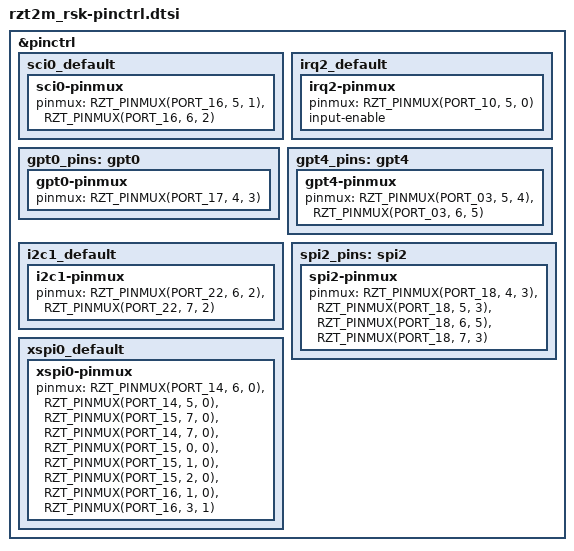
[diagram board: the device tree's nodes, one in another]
/*
 * Copyright (c) 2025 Renesas Electronics Corporation
 * SPDX-License-Identifier: Apache-2.0
 */

#include <zephyr/dt-bindings/gpio/gpio.h>
#include <zephyr/dt-bindings/pinctrl/renesas/pinctrl-rzt-common.h>

&pinctrl {
	/omit-if-no-ref/ sci0_default: sci0_default {
		sci0-pinmux {
			pinmux = <RZT_PINMUX(PORT_16, 5, 1)>, /* TXD */
				 <RZT_PINMUX(PORT_16, 6, 2)>; /* RXD */
		};
	};

	/omit-if-no-ref/ irq2_default: irq2_default {
		irq2-pinmux {
			pinmux = <RZT_PINMUX(PORT_10, 5, 0)>;
			input-enable;
		};
	};

	/omit-if-no-ref/ gpt0_pins: gpt0 {
		gpt0-pinmux {
			pinmux = <RZT_PINMUX(PORT_17, 4, 3)>; /* GTIOCA */
		};
	};

	/omit-if-no-ref/ gpt4_pins: gpt4 {
		gpt4-pinmux {
			pinmux = <RZT_PINMUX(PORT_03, 5, 4)>, /* GTIOCA */
				 <RZT_PINMUX(PORT_03, 6, 5)>; /* GTIOCB */
		};
	};

	/omit-if-no-ref/ i2c1_default: i2c1_default {
		i2c1-pinmux {
			pinmux = <RZT_PINMUX(PORT_22, 6, 2)>, /* SCL */
				 <RZT_PINMUX(PORT_22, 7, 2)>; /* SDA */
		};
	};

	/omit-if-no-ref/ spi2_pins: spi2 {
		spi2-pinmux {
			pinmux = <RZT_PINMUX(PORT_18, 4, 3)>, /* CK2 */
				 <RZT_PINMUX(PORT_18, 5, 3)>, /* MOSI2 */
				 <RZT_PINMUX(PORT_18, 6, 5)>, /* MISO2 */
				 <RZT_PINMUX(PORT_18, 7, 3)>; /* SSL20 */
		};
	};

	/omit-if-no-ref/ xspi0_default: xspi0_default {
		xspi0-pinmux {
			pinmux = <RZT_PINMUX(PORT_14, 6, 0)>, /* XSPI0_CKP */
				 <RZT_PINMUX(PORT_14, 5, 0)>, /* XSPI0_CKN */
				 <RZT_PINMUX(PORT_15, 7, 0)>, /* XSPI0_CS0 */
				 <RZT_PINMUX(PORT_14, 7, 0)>, /* XSPI0_IO0 */
				 <RZT_PINMUX(PORT_15, 0, 0)>, /* XSPI0_IO1 */
				 <RZT_PINMUX(PORT_15, 1, 0)>, /* XSPI0_IO2 */
				 <RZT_PINMUX(PORT_15, 2, 0)>, /* XSPI0_IO3 */
				 <RZT_PINMUX(PORT_16, 1, 0)>, /* XSPI0_RESET0 */
				 <RZT_PINMUX(PORT_16, 3, 1)>; /* XSPI0_RSTO0 */
		};
	};

};
